# nrf9120_mlm1 register map
Vendor: Nordic Semiconductor; Series: nrf91; File version: 1
CPU: CM4 r0p1, little endian, MPU, FPU, 3 interrupt priority bits
Registers are 32-bit, read-write, reset 0x0 unless marked. A register's access mark holds for its fields unless they carry their own. Offsets are from the block's base; [hi:lo] are bit positions; lines under a group give offsets from that group; {n}, {i} and the like mark numbered series.

## EGU0 — Event Generator Unit
Base 0x40015000
{0x0+4i} TASKS_TRIGGER[{i}] (i=0..15) wo — Description collection: Trigger n for triggering the corresponding TRIGGERED[n] event
  [0] TASKS_TRIGGER — Trigger n for triggering the corresponding TRIGGERED[n] event
    1=Trigger task
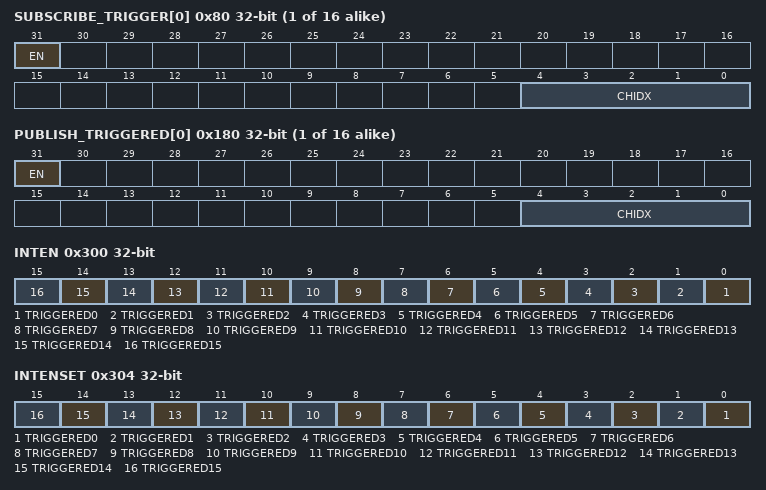
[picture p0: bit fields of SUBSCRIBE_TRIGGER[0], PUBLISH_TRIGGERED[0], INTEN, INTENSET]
{0x80+4i} SUBSCRIBE_TRIGGER[{i}] (i=0..15) — Description collection: Subscribe configuration for task TRIGGER[n]
  [31] EN
    0=Disabled (Disable subscription); 1=Enabled (Enable subscription)
  [4:0] CHIDX — Channel that task TRIGGER[n] will subscribe to
{0x100+4i} EVENTS_TRIGGERED[{i}] (i=0..15) — Description collection: Event number n generated by triggering the corresponding TRIGGER[n] task
  [0] EVENTS_TRIGGERED — Event number n generated by triggering the corresponding TRIGGER[n] task
    0=NotGenerated (Event not generated); 1=Generated (Event generated)
{0x180+4i} PUBLISH_TRIGGERED[{i}] (i=0..15) — Description collection: Publish configuration for event TRIGGERED[n]
  [31] EN
    0=Disabled (Disable publishing); 1=Enabled (Enable publishing)
  [4:0] CHIDX — Channel that event TRIGGERED[n] will publish to.
0x300 INTEN — Enable or disable interrupt
  [all] fields
    0=Disabled; 1=Enabled
  [n] TRIGGERED{n} (n=0..15) — Enable or disable interrupt for event TRIGGERED[{n}]
0x304 INTENSET — Enable interrupt
  [all] fields
    on read: 0=Disabled (Read: Disabled); 1=Enabled (Read: Enabled) | on write: 1=Set (Enable)
  [n] TRIGGERED{n} (n=0..15) — Write '1' to enable interrupt for event TRIGGERED[{n}]
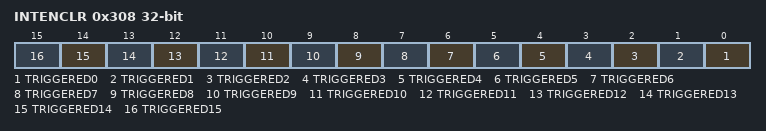
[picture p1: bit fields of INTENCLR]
0x308 INTENCLR — Disable interrupt
  [all] fields
    on read: 0=Disabled (Read: Disabled); 1=Enabled (Read: Enabled) | on write: 1=Clear (Disable)
  [n] TRIGGERED{n} (n=0..15) — Write '1' to disable interrupt for event TRIGGERED[{n}]

## SWI0 — Software interrupt
Base 0x40015000; alternate view of EGU0

## IPC — Inter Processor Communication
Base 0x40019000
{0x0+4i} TASKS_SEND[{i}] (i=0..7) wo — Description collection: Trigger events on channel enabled in SEND_CNF[n].
  [0] TASKS_SEND — Trigger events on channel enabled in SEND_CNF[n].
    1=Trigger task
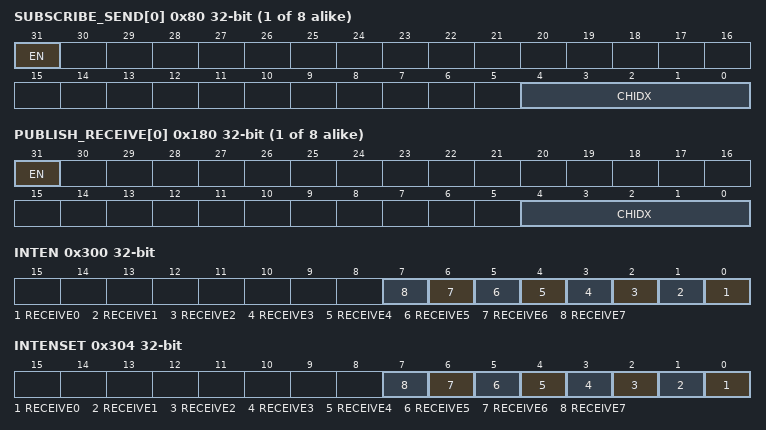
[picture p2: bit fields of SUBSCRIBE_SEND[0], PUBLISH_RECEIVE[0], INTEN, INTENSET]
{0x80+4i} SUBSCRIBE_SEND[{i}] (i=0..7) — Description collection: Subscribe configuration for task SEND[n]
  [31] EN
    0=Disabled (Disable subscription); 1=Enabled (Enable subscription)
  [4:0] CHIDX — Channel that task SEND[n] will subscribe to
{0x100+4i} EVENTS_RECEIVE[{i}] (i=0..7) — Description collection: Event received on one or more of the enabled channels in RECEIVE_CNF[n].
  [0] EVENTS_RECEIVE — Event received on one or more of the enabled channels in RECEIVE_CNF[n].
    0=NotGenerated (Event not generated); 1=Generated (Event generated)
{0x180+4i} PUBLISH_RECEIVE[{i}] (i=0..7) — Description collection: Publish configuration for event RECEIVE[n]
  [31] EN
    0=Disabled (Disable publishing); 1=Enabled (Enable publishing)
  [4:0] CHIDX — Channel that event RECEIVE[n] will publish to.
0x300 INTEN — Enable or disable interrupt
  [all] fields
    0=Disabled; 1=Enabled
  [n] RECEIVE{n} (n=0..7) — Enable or disable interrupt for event RECEIVE[{n}]
0x304 INTENSET — Enable interrupt
  [all] fields
    on read: 0=Disabled (Read: Disabled); 1=Enabled (Read: Enabled) | on write: 1=Set (Enable)
  [n] RECEIVE{n} (n=0..7) — Write '1' to enable interrupt for event RECEIVE[{n}]
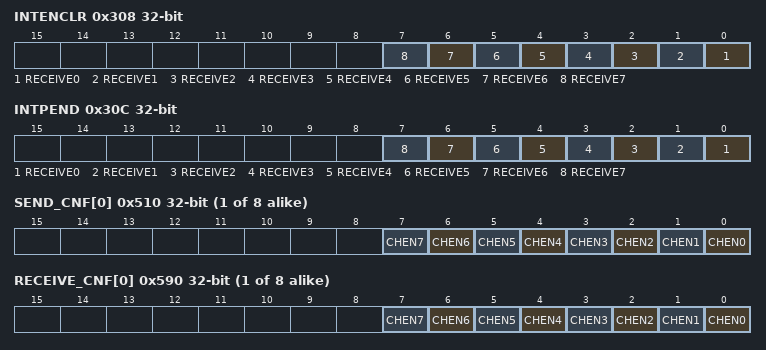
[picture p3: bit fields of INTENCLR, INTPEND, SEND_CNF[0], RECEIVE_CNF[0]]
0x308 INTENCLR — Disable interrupt
  [all] fields
    on read: 0=Disabled (Read: Disabled); 1=Enabled (Read: Enabled) | on write: 1=Clear (Disable)
  [n] RECEIVE{n} (n=0..7) — Write '1' to disable interrupt for event RECEIVE[{n}]
0x30C INTPEND ro — Pending interrupts
  [all] fields
    on read: 0=NotPending (Read: Not pending); 1=Pending (Read: Pending)
  [n] RECEIVE{n} (n=0..7) — Read pending status of interrupt for event RECEIVE[{n}]
{0x510+4i} SEND_CNF[{i}] (i=0..7) — Description collection: Send event configuration for TASKS_SEND[n].
  [all] fields
    0=Disable broadcast; 1=Enable broadcast
  [n] CHEN{n} (n=0..7) — Enable broadcasting on channel {n}.
{0x590+4i} RECEIVE_CNF[{i}] (i=0..7) — Description collection: Receive event configuration for EVENTS_RECEIVE[n].
  [all] fields
    0=Disable events; 1=Enable events
  [n] CHEN{n} (n=0..7) — Enable subscription to channel {n}.
{0x610+4i} GPMEM[{i}] (i=0..1) — Description collection: General purpose memory.
  [31:0] GPMEM — General purpose memory

## VMC — Volatile Memory controller
Base 0x40031000
{0x600+0x10*i} RAM[{i}] (i=0..7) group — Unspecified
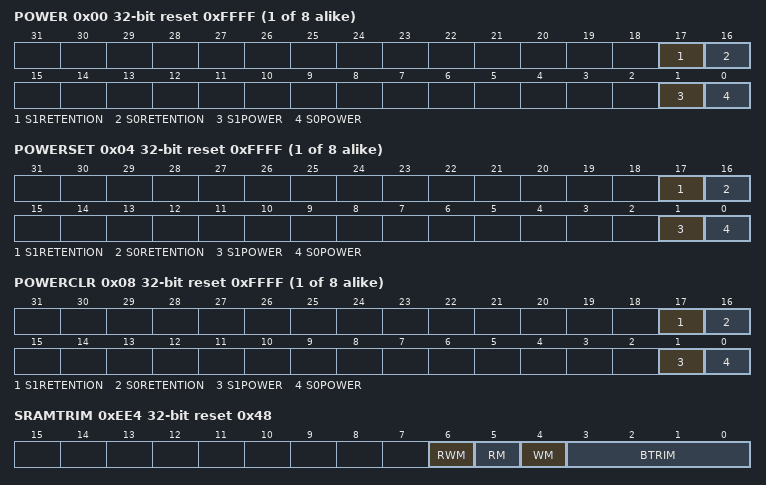
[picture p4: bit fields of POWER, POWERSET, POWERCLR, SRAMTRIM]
  0x00 POWER reset 0xFFFF — Description cluster: RAMn power control register
    [all] fields
      0=Off; 1=On
    [17] S1RETENTION — Keep retention on RAM section S1 of RAM n when RAM section is switched off
    [16] S0RETENTION — Keep retention on RAM section S0 of RAM n when RAM section is switched off
    [1] S1POWER — Keep RAM section S1 of RAM n on or off in System ON mode
    [0] S0POWER — Keep RAM section S0 of RAM n on or off in System ON mode
  0x04 POWERSET wo reset 0xFFFF — Description cluster: RAMn power control set register
    [all] fields
      1=On
    [17] S1RETENTION — Keep retention on RAM section S1 of RAM n when RAM section is switched off
    [16] S0RETENTION — Keep retention on RAM section S0 of RAM n when RAM section is switched off
    [1] S1POWER — Keep RAM section S1 of RAM n on or off in System ON mode
    [0] S0POWER — Keep RAM section S0 of RAM n on or off in System ON mode
  0x08 POWERCLR wo reset 0xFFFF — Description cluster: RAMn power control clear register
    [all] fields
      1=Off
    [17] S1RETENTION — Keep retention on RAM section S1 of RAM n when RAM section is switched off
    [16] S0RETENTION — Keep retention on RAM section S0 of RAM n when RAM section is switched off
    [1] S1POWER — Keep RAM section S1 of RAM n on or off in System ON mode
    [0] S0POWER — Keep RAM section S0 of RAM n on or off in System ON mode
0xEE4 SRAMTRIM reset 0x48 — Backdoor trim values for SRAM
  [6] RWM — Read/Write Margin Adjustment
    0=Disabled; 1=Enabled
  [5] RM — Read Margin Adjustment
    0=Disabled; 1=Enabled
  [4] WM — Write Margin Adjustment
    0=Disabled; 1=Enabled
  [3:0] BTRIM — Source Bias Trim Adjustment for retention
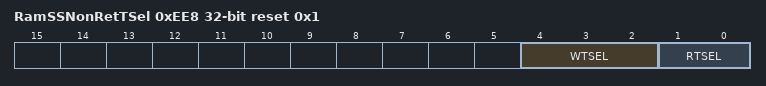
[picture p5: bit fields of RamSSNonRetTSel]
0xEE8 RamSSNonRetTSel reset 0x1 — Timing control values for TSMC RAMs
  [4:2] WTSEL — Write cycle timing selection
  [1:0] RTSEL — Read cycle timing selection
